# SATAMAC_wrapper register map
Vendor: Texas Instruments
Peripheral module from a debugger description file (folder omap5430_ES2_PUBLIC).
Registers are 32-bit, access per field, reset 0x28 unless marked. A register's access mark holds for its fields unless they carry their own. Offsets are as the file gives them; lines under a group give offsets from that group; [hi:lo] are bit positions; {n}, {i} and the like mark numbered series; 'fields as' and 'values as' point back to an identical list; <NAME> marks a mode.

## SATAMAC_wrapper
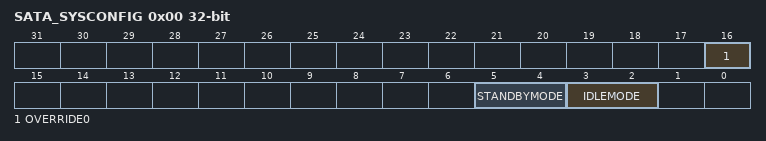
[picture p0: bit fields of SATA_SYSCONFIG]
0x00 SATA_SYSCONFIG — This register controls the idle and standby modes of Highlander 08 modules.
  [16] OVERRIDE0 rw — Override for clock stopping. Normally the functional clock can be stopped only if the link is put into PARTIAL or SLUMBER power state. However, if there is no device attached (such as in a removable media situation) or the device is not started, the user can stop the functional clocks but not be able to enter a low-power state. In this case, software can set the OVERRIDE bit to 1, removing the requirement for a low-power state WARNING: If there is a device attached, the OVERRIDE bit is used, and the functional clock is stopped when the link is not in a low-power state it ruins the link and causes undetermined behavior. A port reset or full SATASS reset might be required to recover.
    0=Normal mode; 1=Override mode
  [5:4] STANDBYMODE rw — Configuration of the local initiator-state management mode. By definition, the initiator can generate a read/write transaction as long as it is out of STANDBY state.
    0=Force-standby mode: Local initiator is unconditionally placed in STANDBY state. Backup mode, for debug only; 1=no (No-standby mode: local initiator is unconditionally placed out of STANDBY state. Backup mode, for debug only.); 3=smart_wakeup (Smart-Standby wakeup-capable mode: Local initiator standby status depends on local conditions, that is, the module's functional requirement from the initiator. The IP module can generate (master related) wakeup events when in STANDBY state. Mode is relevant only if the appropriate IP module mwakeup output is implemented.); 2=Smart-standby mode: Local initiator standby status depends on local conditions, that is, the module's functional requirement from the initiator. The IP module does not generate (initiated-related) wakeup events.
  [3:2] IDLEMODE rw — Configuration of the local target state management mode. By definition, the target can handle read/write transaction as long as it is out of IDLE state.
    0=Force-idle mode: The local target IDLE state follows (acknowledges) the system idle requests unconditionally, that is, regardless of the internal requirements of th e IP module. Backup mode, for debug only.; 1=no (No-idle mode: The local target never enters IDLE state. Backup mode, for debug only.); 3=smartwakeup (Smart-idle wakeup-capable mode: The local target IDLE state eventually follows (acknowledges) the system idle requests, depending on the internal requirements of the IP module. IP module can generate (IRQ- or DMA-request-related) wakeup events when in IDLE state. Mode is only relevant if the appropriate IP module swakeup output(s) is (are) implemented.); 2=Smart-idle mode: The local target IDLE state eventually follows (acknowledges) the system idle requests, depending on the internal requirements of the IP module. IP module does not generate (IRQ- or DMA-request-related) wakeup events.
0x04 SATA_CDRLOCK reset 0x7D0 — Programmable delay for CDR lock indication
  [11:0] CDR_LOCK_DELAY rw — CDR lock delay, in parallel (10-bit) serdes interface clock cycles. Parallel clock is 300 MHz (3.3 ns period) for SATA-3 Gbps, 150 MHz (6.7 ns) for SATA-1.5 Gbps.
    0=off (No CDR lock delay); 0x7D0=nominal (Default CDR lock delay: 13.33 us (1.5 Gbps mode) or 6.67 us (3 Gbps mode))
